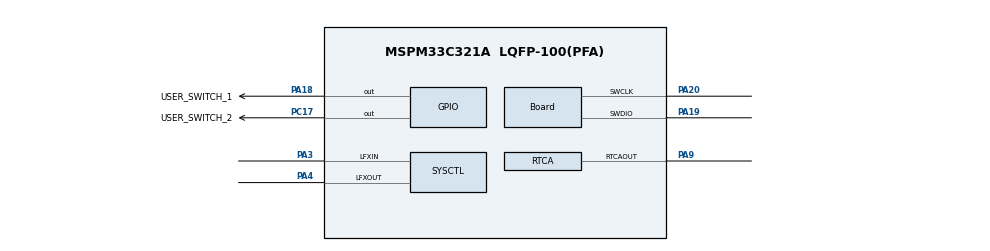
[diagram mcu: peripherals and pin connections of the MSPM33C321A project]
//@cliArgs --device "MSPM33C321A" --package "LQFP-100(PFA)" --part "Default"
//@v2CliArgs --device "MSPM33C321A" --package "LQFP-100(PFA)"
// @cliArgs --board /ti/boards/LP_MSPM33C321A --rtos nortos


/**
 * Import the modules used in this configuration.
 */
const GPIO   = scripting.addModule("/ti/driverlib/GPIO", {}, false);
const GPIO1  = GPIO.addInstance();
const GPIO2  = GPIO.addInstance();
const RTCA   = scripting.addModule("/ti/driverlib/RTCA");
const SYSCTL = scripting.addModule("/ti/driverlib/SYSCTL");

/**
 * Write custom configuration values to the imported modules.
 */
GPIO1.$name                               = "GPIO_SWITCHES1";
GPIO1.associatedPins[0].$name             = "USER_SWITCH_1";
GPIO1.associatedPins[0].launchPadShortcut = "Button1En";
GPIO1.associatedPins[0].interruptEn       = true;
GPIO1.associatedPins[0].internalResistor  = "PULL_DOWN";
GPIO1.associatedPins[0].polarity          = "RISE";
GPIO1.associatedPins[0].pin.$assign       = "PA18";

const Board                       = scripting.addModule("/ti/driverlib/Board", {}, false);
Board.peripheral.$assign          = "DEBUGSS";
Board.peripheral.swclkPin.$assign = "PA20";
Board.peripheral.swdioPin.$assign = "PA19";

GPIO2.$name                               = "GPIO_SWITCHES2";
GPIO2.associatedPins[0].$name             = "USER_SWITCH_2";
GPIO2.associatedPins[0].launchPadShortcut = "Button2En";
GPIO2.associatedPins[0].interruptEn       = true;
GPIO2.associatedPins[0].polarity          = "FALL";
GPIO2.associatedPins[0].pin.$assign       = "PC17";

RTCA.calSec                        = 58;
RTCA.calMin                        = 32;
RTCA.calHour                       = 10;
RTCA.calDOW                        = "1";
RTCA.calDOM                        = 5;
RTCA.calMonth                      = "4";
RTCA.calYear                       = 2021;
RTCA.offsetCalFreq                 = "512";
RTCA.peripheral.$assign            = "LFSS";
RTCA.peripheral.rtcaOutPin.$assign = "PA9";

SYSCTL.LFCLKSource                  = "LFXT";
SYSCTL.forceDefaultClkConfig        = true;
SYSCTL.peripheral.$assign           = "SYSCTL";
SYSCTL.peripheral.lfxInPin.$assign  = "PA3";
SYSCTL.peripheral.lfxOutPin.$assign = "PA4";

const ProjectConfig              = scripting.addModule("/ti/project_config/ProjectConfig", {}, false);
ProjectConfig.migrationCondition = true;
